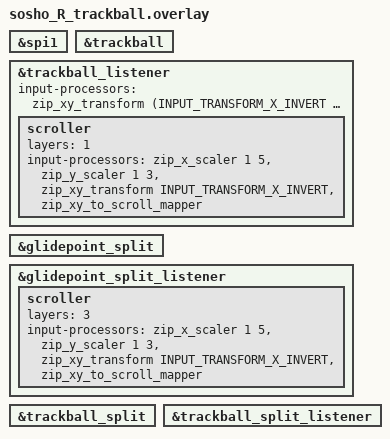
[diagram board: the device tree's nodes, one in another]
#include "sosho_R.dtsi"

/*
glidepoint_listnerは右手のトラックパッド
glidepoint_split_listenerとtrackball_split_listenerは
左手のトラックパッドとトラックボールの受けです。
ここにinput-processorというオプションをつけると、いろんな動きができます。
代表的なものを書いておきます。

・ポインタの移動を早くしたいとき
&zip_xy_scalerを使います。
分子 分母の順に数字を指定します。2 1なら2倍です。
input-processors = <&zip_xy_scaler 2 1>;

・スクロールを割り当てたいとき
zip_xy_to_scroll_mapperを使います。
ポインティングデバイスの動きをスクロールに変換してくれます。
input-processors = <&zip_xy_to_scroll_mapper>;

・移動を反転したいとき
zip_xy_transformを使います。
これは&trackball_listenerで実際に使っています。

これらオプションは複数併記することもできます。
input-processors = <&zip_xy_scaler 1 3>,<&zip_xy_to_scroll_mapper>;

詳しい情報はzmkのドキュメントを確認してください。
https://zmk.dev/docs/keymaps/input-processors
*/

&spi1 { status = "okay"; };
&trackball { status = "okay"; };
&trackball_listener {
	status = "okay";
	input-processors = <&zip_xy_transform (INPUT_TRANSFORM_X_INVERT | INPUT_TRANSFORM_Y_INVERT)>;

	//Layer1(Symbol)が有効な間だけ、トラックボールの動きを上下左右スクロールに変換する
	scroller {
		layers = <1>;
		//X反転で左右の向きを修正。縦1/3・横1/5で横だけさらに遅く(分母を上げるほど遅い)
		input-processors = <&zip_x_scaler 1 5>, <&zip_y_scaler 1 3>, <&zip_xy_transform INPUT_TRANSFORM_X_INVERT>, <&zip_xy_to_scroll_mapper>;
	};
};

&glidepoint_split { status = "okay"; };
&glidepoint_split_listener {
    status = "okay";
	//input-processors = <&zip_xy_scaler 2 1>;

	//Layer3(Nav)が有効な間だけ、左手トラックパッドの動きを上下左右スクロールに変換する
	scroller {
		layers = <3>;
		//Windowsノートのタッチパッド流でXY両方を指に追従(上→下/右→左)。縦1/3・横1/5で横だけさらに遅く
		input-processors = <&zip_x_scaler 1 5>, <&zip_y_scaler 1 3>, <&zip_xy_transform INPUT_TRANSFORM_X_INVERT>, <&zip_xy_to_scroll_mapper>;
	};
};

&trackball_split { status = "okay"; };
&trackball_split_listener {
	status = "okay"; 
	//input-processors = <&zip_xy_to_scroll_mapper>;
};
